VERSION ""

NS_ :

BS_:
BU_: SAS
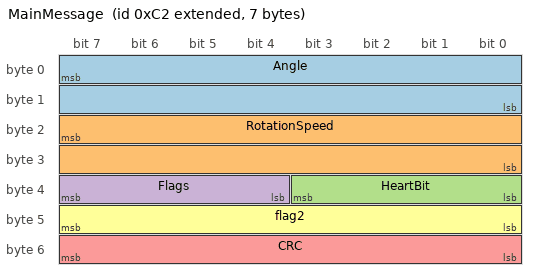
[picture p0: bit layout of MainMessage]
BO_ 2147483842 MainMessage: 7 SAS
   SG_ Angle : 7|16@0+ (0.1,-3276.8) [-780|780] "grad" Vector__XXX
   SG_ RotationSpeed : 23|16@0+ (0.1,-3276.8) [0|1] "grad/sec" SAS
   SG_ HeartBit : 35|4@0+ (1,0) [0|1] "" SAS
   SG_ Flags : 39|4@0+ (1,0) [0|1] "" SAS
   SG_ CRC : 55|8@0+ (1,0) [0|1] "" SAS
   SG_ flag2 : 47|8@0+ (1,0) [0|1] "" SAS

CM_ BU_ SAS "Steering angle sensor";
BA_DEF_ BO_ "GenMsgBackgroundColor" STRING ;
BA_DEF_ BO_ "GenMsgForegroundColor" STRING ;
BA_DEF_ BO_ "filterlabeling" INT 0 0;
BA_DEF_ BO_ "filterlabeling" INT 0 0;
BA_DEF_DEF_ "GenMsgBackgroundColor" "#ffffff";
BA_DEF_DEF_ "GenMsgForegroundColor" "#000000";
BA_DEF_DEF_ "filterlabeling" 1;
BA_DEF_DEF_ "filterlabeling" 1;
